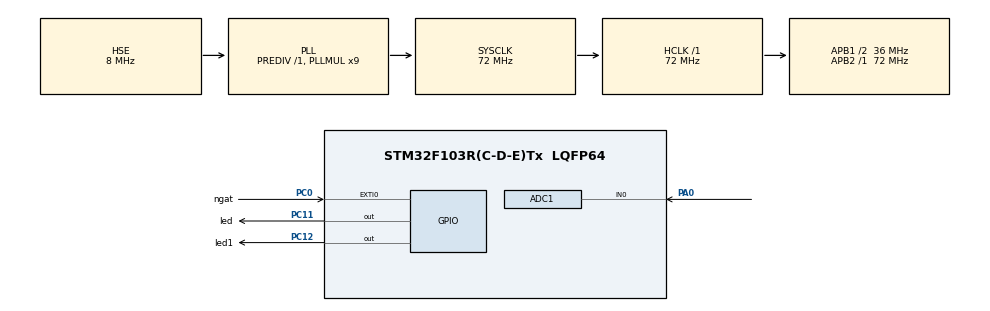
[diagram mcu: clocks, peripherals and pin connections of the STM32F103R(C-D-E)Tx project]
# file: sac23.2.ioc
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ADC1.Channel-0\#ChannelRegularConversion=ADC_CHANNEL_0
ADC1.ContinuousConvMode=ENABLE
ADC1.NbrOfConversionFlag=1
ADC1.Rank-0\#ChannelRegularConversion=1
ADC1.SamplingTime-0\#ChannelRegularConversion=ADC_SAMPLETIME_28CYCLES_5
ADC1.master=1
Mcu.Family=STM32F1
Mcu.Name=STM32F103R(C-D-E)Tx
Mcu.Package=LQFP64
NVIC.ADC1_2_IRQn=true\:0\:0\:false\:false\:true\:true\:true
NVIC.EXTI0_IRQn=true\:0\:0\:false\:false\:true\:true\:true
NVIC.PriorityGroup=NVIC_PRIORITYGROUP_4
PA0-WKUP.Signal=ADCx_IN0
PA13.Mode=Serial_Wire
PA13.Signal=SYS_JTMS-SWDIO
PA14.Mode=Serial_Wire
PA14.Signal=SYS_JTCK-SWCLK
PC0.GPIO_Label=ngat
PC0.GPIO_ModeDefaultEXTI=GPIO_MODE_IT_RISING_FALLING
PC0.GPIO_PuPd=GPIO_PULLDOWN
PC0.Signal=GPXTI0
PC11.GPIO_Label=led
PC11.Signal=GPIO_Output
PC12.GPIO_Label=led1
PC12.Signal=GPIO_Output
PD0-OSC_IN.Mode=HSE-External-Oscillator
PD0-OSC_IN.Signal=RCC_OSC_IN
PD1-OSC_OUT.Mode=HSE-External-Oscillator
PD1-OSC_OUT.Signal=RCC_OSC_OUT
ProjectManager.HeapSize=0x200
ProjectManager.StackSize=0x400
ProjectManager.TargetToolchain=MDK-ARM V5
RCC.ADCPresc=RCC_ADCPCLK2_DIV6
RCC.AHBFreq_Value=72000000
RCC.APB1CLKDivider=RCC_HCLK_DIV2
RCC.APB1Freq_Value=36000000
RCC.APB1TimFreq_Value=72000000
RCC.APB2Freq_Value=72000000
RCC.APB2TimFreq_Value=72000000
RCC.HCLKFreq_Value=72000000
RCC.PLLMUL=RCC_PLL_MUL9
RCC.PLLSourceVirtual=RCC_PLLSOURCE_HSE
RCC.SYSCLKFreq_VALUE=72000000
RCC.SYSCLKSource=RCC_SYSCLKSOURCE_PLLCLK
RCC.USBFreq_Value=72000000
SH.ADCx_IN0.0=ADC1_IN0,IN0
board=custom

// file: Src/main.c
/* USER CODE BEGIN Header */
/**
  ******************************************************************************
  * @file           : main.c
  * @brief          : Main program body
  ******************************************************************************
  * @attention
  *
  * <h2><center>&copy; Copyright (c) 2020 STMicroelectronics.
  * All rights reserved.</center></h2>
  *
  * This software component is licensed by ST under BSD 3-Clause license,
  * the "License"; You may not use this file except in compliance with the
  * License. You may obtain a copy of the License at:
  *                        opensource.org/licenses/BSD-3-Clause
  *
  ******************************************************************************
  */
/* USER CODE END Header */

#include "main.h"

/* USER CODE BEGIN Includes */
#include "stdbool.h"
/* USER CODE END Includes */

ADC_HandleTypeDef hadc1;

/* USER CODE BEGIN PV */
volatile uint32_t adc = 0;
volatile bool start =1;
void HAL_GPIO_EXTI_Callback(uint16_t GPIO_Pin)
{
	if (GPIO_Pin == ngat_Pin){
		start=0;
//		HAL_ADC_Start(&hadc1);
//		adc = HAL_ADC_GetValue(&hadc1);
//		HAL_GPIO_WritePin(led_GPIO_Port,led_Pin,1);
//		start=1;
	}
//	else{
//		HAL_GPIO_WritePin(led_GPIO_Port,led_Pin,0);
//		start =1;
//	}
}
/* USER CODE END PV */

void SystemClock_Config(void);
static void MX_GPIO_Init(void);
static void MX_ADC1_Init(void);

int main(void)
{

  /* MCU Configuration--------------------------------------------------------*/

  /* Reset of all peripherals, Initializes the Flash interface and the Systick. */
  HAL_Init();

  /* Configure the system clock */
  SystemClock_Config();

  /* Initialize all configured peripherals */
  MX_GPIO_Init();
  MX_ADC1_Init();
  /* USER CODE BEGIN 2 */
HAL_ADC_Start(&hadc1);
  /* USER CODE END 2 */

  /* Infinite loop */
  while (1)
  {
		HAL_ADC_Start(&hadc1);
		adc = HAL_ADC_GetValue(&hadc1);
		start=1;
    /* USER CODE BEGIN 3 */
		while(start){
		HAL_GPIO_TogglePin(led1_GPIO_Port,led1_Pin);
		HAL_Delay(1000);
		}

  }
  /* USER CODE END 3 */
}

void SystemClock_Config(void)
{
  RCC_OscInitTypeDef RCC_OscInitStruct = {0};
  RCC_ClkInitTypeDef RCC_ClkInitStruct = {0};
  RCC_PeriphCLKInitTypeDef PeriphClkInit = {0};

  /** Initializes the CPU, AHB and APB busses clocks
  */
  RCC_OscInitStruct.OscillatorType = RCC_OSCILLATORTYPE_HSE;
  RCC_OscInitStruct.HSEState = RCC_HSE_ON;
  RCC_OscInitStruct.HSEPredivValue = RCC_HSE_PREDIV_DIV1;
  RCC_OscInitStruct.HSIState = RCC_HSI_ON;
  RCC_OscInitStruct.PLL.PLLState = RCC_PLL_ON;
  RCC_OscInitStruct.PLL.PLLSource = RCC_PLLSOURCE_HSE;
  RCC_OscInitStruct.PLL.PLLMUL = RCC_PLL_MUL9;
  if (HAL_RCC_OscConfig(&RCC_OscInitStruct) != HAL_OK)
  {
    Error_Handler();
  }
  /** Initializes the CPU, AHB and APB busses clocks
  */
  RCC_ClkInitStruct.ClockType = RCC_CLOCKTYPE_HCLK|RCC_CLOCKTYPE_SYSCLK
                              |RCC_CLOCKTYPE_PCLK1|RCC_CLOCKTYPE_PCLK2;
  RCC_ClkInitStruct.SYSCLKSource = RCC_SYSCLKSOURCE_PLLCLK;
  RCC_ClkInitStruct.AHBCLKDivider = RCC_SYSCLK_DIV1;
  RCC_ClkInitStruct.APB1CLKDivider = RCC_HCLK_DIV2;
  RCC_ClkInitStruct.APB2CLKDivider = RCC_HCLK_DIV1;

  if (HAL_RCC_ClockConfig(&RCC_ClkInitStruct, FLASH_LATENCY_2) != HAL_OK)
  {
    Error_Handler();
  }
  PeriphClkInit.PeriphClockSelection = RCC_PERIPHCLK_ADC;
  PeriphClkInit.AdcClockSelection = RCC_ADCPCLK2_DIV6;
  if (HAL_RCCEx_PeriphCLKConfig(&PeriphClkInit) != HAL_OK)
  {
    Error_Handler();
  }
}

static void MX_ADC1_Init(void)
{

  ADC_ChannelConfTypeDef sConfig = {0};

  /** Common config
  */
  hadc1.Instance = ADC1;
  hadc1.Init.ScanConvMode = ADC_SCAN_DISABLE;
  hadc1.Init.ContinuousConvMode = ENABLE;
  hadc1.Init.DiscontinuousConvMode = DISABLE;
  hadc1.Init.ExternalTrigConv = ADC_SOFTWARE_START;
  hadc1.Init.DataAlign = ADC_DATAALIGN_RIGHT;
  hadc1.Init.NbrOfConversion = 1;
  if (HAL_ADC_Init(&hadc1) != HAL_OK)
  {
    Error_Handler();
  }
  /** Configure Regular Channel
  */
  sConfig.Channel = ADC_CHANNEL_0;
  sConfig.Rank = ADC_REGULAR_RANK_1;
  sConfig.SamplingTime = ADC_SAMPLETIME_28CYCLES_5;
  if (HAL_ADC_ConfigChannel(&hadc1, &sConfig) != HAL_OK)
  {
    Error_Handler();
  }

}

static void MX_GPIO_Init(void)
{
  GPIO_InitTypeDef GPIO_InitStruct = {0};

  /* GPIO Ports Clock Enable */
  __HAL_RCC_GPIOD_CLK_ENABLE();
  __HAL_RCC_GPIOC_CLK_ENABLE();
  __HAL_RCC_GPIOA_CLK_ENABLE();

  /*Configure GPIO pin Output Level */
  HAL_GPIO_WritePin(GPIOC, led_Pin|led1_Pin, GPIO_PIN_RESET);

  /*Configure GPIO pin : ngat_Pin */
  GPIO_InitStruct.Pin = ngat_Pin;
  GPIO_InitStruct.Mode = GPIO_MODE_IT_RISING_FALLING;
  GPIO_InitStruct.Pull = GPIO_PULLDOWN;
  HAL_GPIO_Init(ngat_GPIO_Port, &GPIO_InitStruct);

  /*Configure GPIO pins : led_Pin led1_Pin */
  GPIO_InitStruct.Pin = led_Pin|led1_Pin;
  GPIO_InitStruct.Mode = GPIO_MODE_OUTPUT_PP;
  GPIO_InitStruct.Pull = GPIO_NOPULL;
  GPIO_InitStruct.Speed = GPIO_SPEED_FREQ_LOW;
  HAL_GPIO_Init(GPIOC, &GPIO_InitStruct);

  /* EXTI interrupt init*/
  HAL_NVIC_SetPriority(EXTI0_IRQn, 0, 0);
  HAL_NVIC_EnableIRQ(EXTI0_IRQn);

}

void Error_Handler(void)
{
}

/************************ (C) COPYRIGHT STMicroelectronics *****END OF FILE****/
